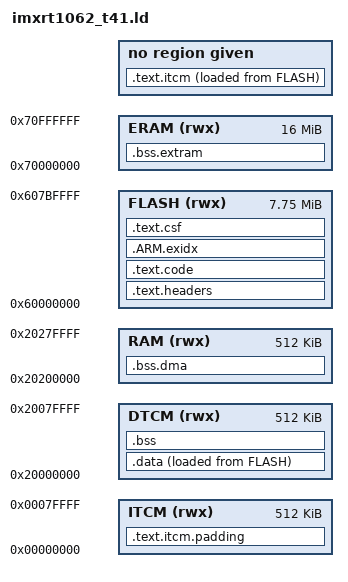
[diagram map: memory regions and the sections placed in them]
MEMORY
{
	ITCM (rwx):  ORIGIN = 0x00000000, LENGTH = 512K
	DTCM (rwx):  ORIGIN = 0x20000000, LENGTH = 512K
	RAM (rwx):   ORIGIN = 0x20200000, LENGTH = 512K
	FLASH (rwx): ORIGIN = 0x60000000, LENGTH = 7936K
	ERAM (rwx):  ORIGIN = 0x70000000, LENGTH = 16384K
}

ENTRY(ImageVectorTable)

SECTIONS
{
	.text.headers : {
		KEEP(*(.flashconfig))
		FILL(0xFF)
		. = ORIGIN(FLASH) + 0x1000;
		KEEP(*(.ivt))
		KEEP(*(.bootdata))
		. = ALIGN(1024);
	} > FLASH

	.text.code : {
		KEEP(*(.startup))
        *(.text*)
		*(.flashmem*)
        *(.progmem*)
		. = ALIGN(4);
		KEEP(*(.init))
		__preinit_array_start = .;
		KEEP (*(.preinit_array))
		__preinit_array_end = .;
		__init_array_start = .;
		KEEP (*(.init_array))
		__init_array_end = .;
		. = ALIGN(4);
	} > FLASH

	.text.itcm ALIGN(32,0) : {
        . = 0x0000;
		*(.fastrun)
		. = ALIGN(16);
	} AT > FLASH

	.ARM.exidx : {
		__exidx_start = .;
		*(.ARM.exidx* .gnu.linkonce.armexidx.*)
		__exidx_end = .;
	} > FLASH

	.text.itcm.padding (NOLOAD) : {
		. = ALIGN(32768);
	}  > ITCM
    
	.data : {
		*(.endpoint_queue)   
		*(SORT_BY_ALIGNMENT(SORT_BY_NAME(.rodata*)))
		*(SORT_BY_ALIGNMENT(SORT_BY_NAME(.data*)))
		KEEP(*(.vectorsram))
    . = ALIGN(16);
	} > DTCM  AT> FLASH

	.bss ALIGN(4) : {
		*(SORT_BY_ALIGNMENT(SORT_BY_NAME(.bss*)))
		*(SORT_BY_ALIGNMENT(SORT_BY_NAME(COMMON)))
		. = ALIGN(32);
		. = . + 32; /* MPU to trap stack overflow */
	} > DTCM

	.bss.dma (NOLOAD) : {
		*(.hab_log)
		*(.dmabuffers)
		. = ALIGN(32);
	} > RAM

	.bss.extram (NOLOAD) : {
		*(.externalram)
		. = ALIGN(32);
	} > ERAM

	.text.csf : {
		FILL(0xFF)
		. = ALIGN(1024);
		KEEP(*(.csf))
        __text_csf_end = .;
	} > FLASH

	_stext = ADDR(.text.itcm);
	_etext = ADDR(.text.itcm) + SIZEOF(.text.itcm);
    _size_of_itcm  = _etext > 32 ? ADDR(.text.itcm) + SIZEOF(.text.itcm) : 0;
	_stextload = LOADADDR(.text.itcm);

	_sdata = ADDR(.data);
	_edata = ADDR(.data) + SIZEOF(.data) + SIZEOF(.ARM.exidx);
	_sdataload = LOADADDR(.data);

	_sbss = ADDR(.bss);
	_ebss = ADDR(.bss) + SIZEOF(.bss);

	_heap_start = ADDR(.bss.dma) + SIZEOF(.bss.dma);
	_heap_end = ORIGIN(RAM) + LENGTH(RAM);

	_extram_start = ADDR(.bss.extram);
	_extram_end = ADDR(.bss.extram) + SIZEOF(.bss.extram);

	_itcm_block_count = (_size_of_itcm + 0x7FFF) >> 15;
	_flexram_bank_config = 0xAAAAAAAA | ((1 << (_itcm_block_count * 2)) - 1);
	_estack = ORIGIN(DTCM) + ((16 - _itcm_block_count) << 15);

	_flashimagelen = __text_csf_end - ORIGIN(FLASH);
	_teensy_model_identifier = 0x25;

	.debug_info     0 : { *(.debug_info) }
	.debug_abbrev   0 : { *(.debug_abbrev) }
	.debug_line     0 : { *(.debug_line) }
	.debug_frame    0 : { *(.debug_frame) }
	.debug_str      0 : { *(.debug_str) }
	.debug_loc      0 : { *(.debug_loc) }

}
